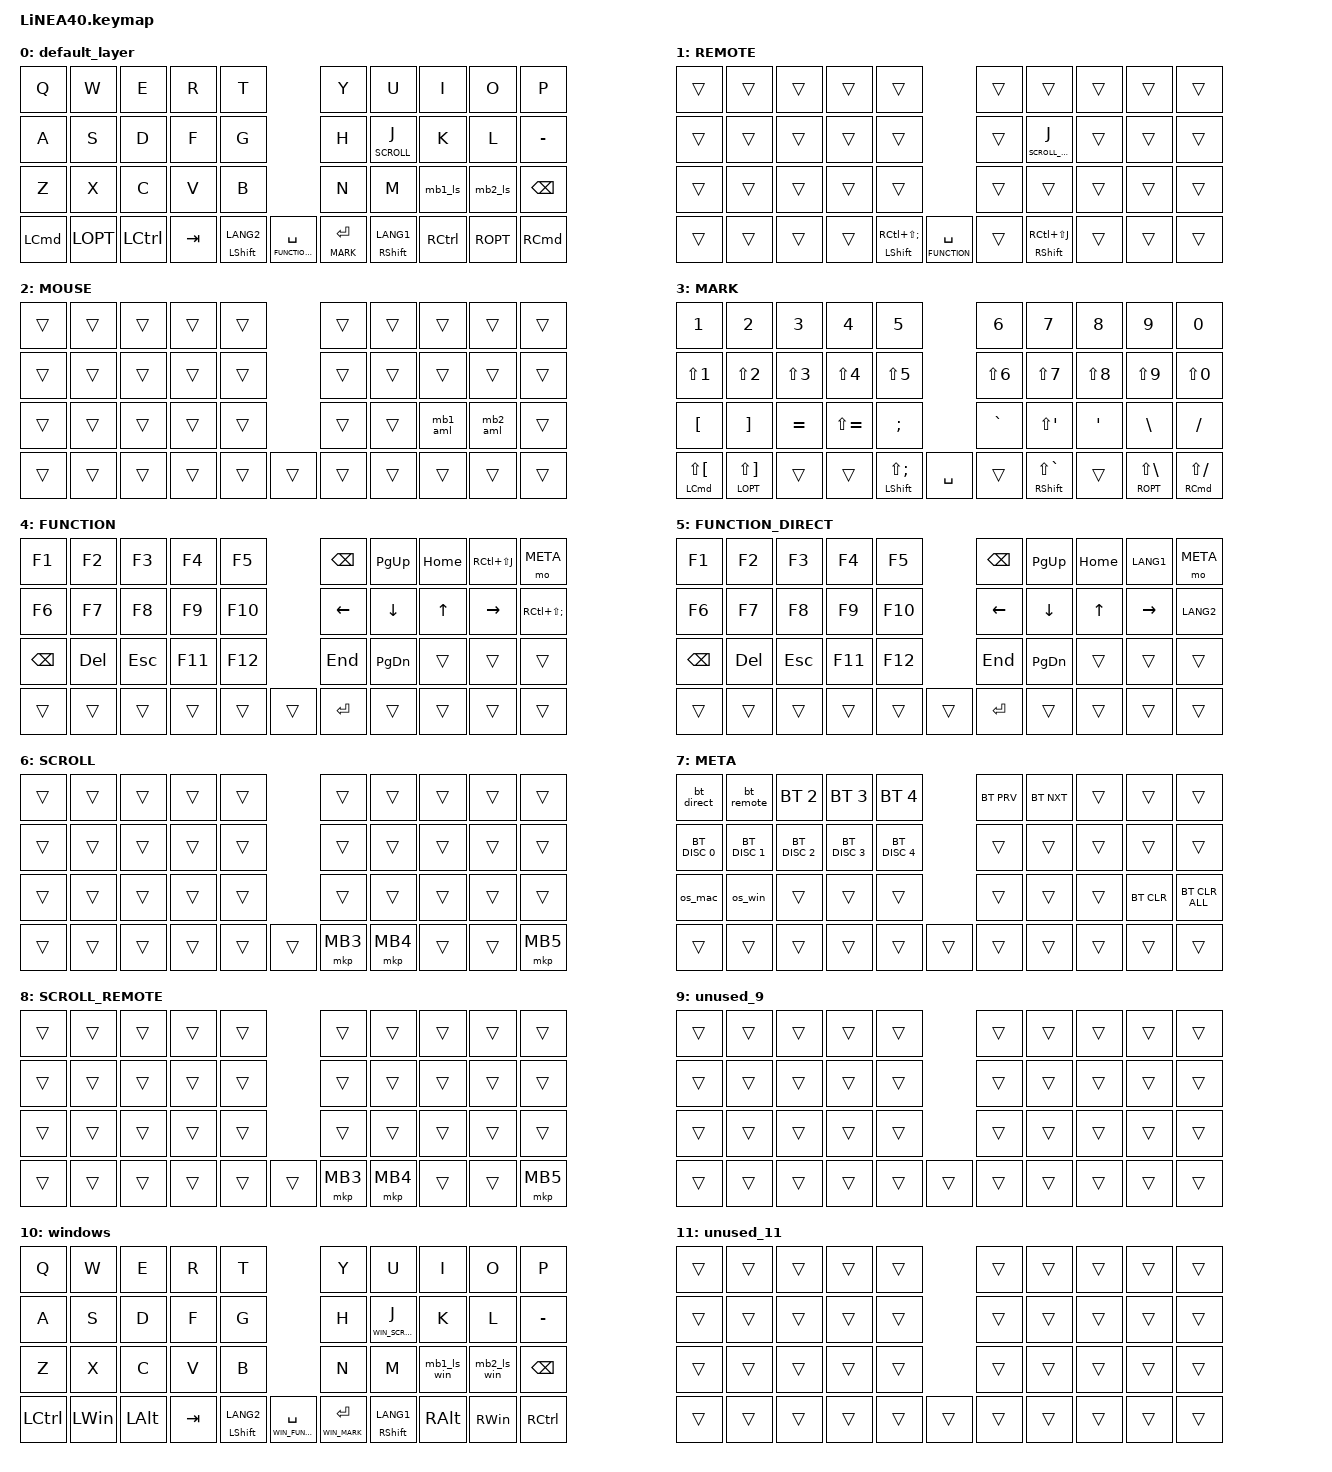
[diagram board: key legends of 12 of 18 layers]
#define ZMK_POINTING_DEFAULT_SCRL_VAL 150

#include <dt-bindings/zmk/input_transform.h>
#include <input/processors.dtsi>
#include <zephyr/dt-bindings/input/input-event-codes.h>
#include <behaviors.dtsi>
#include <dt-bindings/zmk/bt.h>
#include <dt-bindings/zmk/keys.h>
#include <dt-bindings/zmk/modifiers.h>
#include <dt-bindings/zmk/pointing.h>

// 0–8 Mac。10–17 Windows（下一桁が Mac と同じ。REMOTE / Jump Desktop 相当は空けておく）
#define REMOTE 1
#define MOUSE 2
#define MARK 3
#define FUNCTION 4
#define FUNCTION_DIRECT 5
#define SCROLL 6
#define META 7
#define SCROLL_REMOTE 8
// 9 は番号合わせの空き
#define WINDOWS 10
// 11 は REMOTE 相当の空き（Jump Desktop は Windows に無い）
#define WIN_MOUSE 12
#define WIN_MARK 13
// 14 は FUNCTION 相当の空き（Jump Desktop 用 FUNCTION は Windows に無い）
#define WIN_FUNCTION_DIRECT 15
#define WIN_SCROLL 16
#define WIN_META 17
#define AK_LAYER_MARK F21
// 起動時は Mac（直接接続）。英数は LANG2、かなは LANG1。再起動でも Mac に戻る。
// META / WIN_META の X で WINDOWS を基本レイヤーにする。Cmd→Ctrl、Opt→Win、Ctrl→Alt。Z で Mac に戻す。
// REMOTE は Mac の Jump Desktop 専用。英数は右Ctrl+Shift+;、かなは右Ctrl+Shift+J。Windows では乗せない。
// ボールは常に MOUSE を足す。Windows 基本のときは conditional で WIN_MOUSE に載せ替える。
// 文章操作のあと、句読点のままにする時間（ms）
#define AK_PUNCT_IDLE_MS 4000

#define LOPT LALT
#define ROPT RALT

&mt { flavor = "hold-preferred"; };

&lt { flavor = "hold-preferred"; };

//mouse cursol

&mmv {
    delay-ms = <20>;
    trigger-period-ms = <5>;
    time-to-max-speed-ms = <100>;
    acceleration-exponent = <2>;
};

//mouse scroll

&msc {
    delay-ms = <3>;
    trigger-period-ms = <3>;
    time-to-max-speed-ms = <100>;
    acceleration-exponent = <0>;
};

/ {
    input_processors {
        zip_wheel_scaler: zip_wheel_scaler {
            compatible = "zmk,input-processor-scaler";
            #input-processor-cells = <2>;
            type = <INPUT_EV_REL>;
            codes = <INPUT_REL_WHEEL>;
            track-remainders;
        };

        // ボール操作で MOUSE を乗せ、クリック以外のキーで外す（句読点クールタイムを打ち切る）
        zip_ak_mouse: zip_ak_mouse {
            compatible = "zmk,input-processor-temp-layer";
            #input-processor-cells = <2>;
            excluded-positions = <27 28>;
        };
    };
};

&msc_input_listener {
    speed_up {
        layers = <FUNCTION FUNCTION_DIRECT WIN_FUNCTION_DIRECT>;
        input-processors = <&zip_wheel_scaler 3 1>; //スクロールを3倍速にする
    };
};

&trackball_listener {
    input-processors = <&zip_ak_mouse MOUSE 1500>;

    scroller {
        layers = <SCROLL WIN_SCROLL>;
        input-processors =
            <&zip_ak_mouse MOUSE 1500>,
            // スクロール用に感度を小さくする,,,,,,,,,,,,,,
            <&zip_xy_scaler 1 30>,
            // スクロール方向を逆転,,,,,,,,,,,,,,
            <&zip_xy_transform INPUT_TRANSFORM_Y_INVERT>,
            // マウス移動をスクロールに割り当て,,,,,,,,,,,,,,
            <&zip_xy_to_scroll_mapper>;
    };

    // プロファイル1のホイール。縦は直接接続と逆、速度は半分（1/60）
    remote_scroller {
        layers = <SCROLL_REMOTE>;
        input-processors =
            <&zip_ak_mouse MOUSE 1500>,
            <&zip_xy_scaler 1 60>,
            <&zip_xy_to_scroll_mapper>;
    };
};

/ {
    combos { compatible = "zmk,combos"; };

    macros {
        // レイヤーを押しながら未使用キーをタップし、句読点判定の直前キーにする
        mo_ak: mo_ak {
            compatible = "zmk,behavior-macro-one-param";
            #binding-cells = <1>;
            wait-ms = <0>;
            tap-ms = <5>;
            bindings
                = <&macro_param_1to1>
                , <&macro_press &mo MACRO_PLACEHOLDER>
                , <&macro_tap &kp AK_LAYER_MARK>
                , <&macro_pause_for_release>
                , <&macro_param_1to1>
                , <&macro_release &mo MACRO_PLACEHOLDER>
                ;
        };
        // プロファイル0（直接接続）。キーを離してから REMOTE 層を外し、基本レイヤーに戻す
        bt_direct: bt_direct {
            compatible = "zmk,behavior-macro";
            #binding-cells = <0>;
            wait-ms = <0>;
            tap-ms = <0>;
            bindings
                = <&macro_tap &bt BT_SEL 0>
                , <&macro_pause_for_release>
                , <&macro_tap &to 0>
                ;
        };
        // プロファイル1（リモート接続）。キーを離してから REMOTE 層を足す
        bt_remote: bt_remote {
            compatible = "zmk,behavior-macro";
            #binding-cells = <0>;
            wait-ms = <0>;
            tap-ms = <0>;
            bindings
                = <&macro_tap &bt BT_SEL 1>
                , <&macro_pause_for_release>
                , <&macro_tap &to 0>
                , <&macro_tap &tog REMOTE>
                ;
        };
        // Windows 基本レイヤーのままプロファイル0へ。&to 0 だと Windows が外れる
        bt_direct_win: bt_direct_win {
            compatible = "zmk,behavior-macro";
            #binding-cells = <0>;
            wait-ms = <0>;
            tap-ms = <0>;
            bindings
                = <&macro_tap &bt BT_SEL 0>
                , <&macro_pause_for_release>
                , <&macro_tap &to WINDOWS>
                ;
        };
        // Windows 基本レイヤーのままプロファイル1へ。REMOTE は Mac の Jump Desktop 用なので乗せない
        bt_remote_win: bt_remote_win {
            compatible = "zmk,behavior-macro";
            #binding-cells = <0>;
            wait-ms = <0>;
            tap-ms = <0>;
            bindings
                = <&macro_tap &bt BT_SEL 1>
                , <&macro_pause_for_release>
                , <&macro_tap &to WINDOWS>
                ;
        };
        // META の Z。離してから Mac の基本レイヤーだけにする（REMOTE も外れる）
        os_mac: os_mac {
            compatible = "zmk,behavior-macro";
            #binding-cells = <0>;
            wait-ms = <0>;
            tap-ms = <0>;
            bindings
                = <&macro_pause_for_release>
                , <&macro_tap &to 0>
                ;
        };
        // META の X。離してから WINDOWS を基本レイヤーにする（REMOTE も外れる）
        os_win: os_win {
            compatible = "zmk,behavior-macro";
            #binding-cells = <0>;
            wait-ms = <0>;
            tap-ms = <0>;
            bindings
                = <&macro_pause_for_release>
                , <&macro_tap &to WINDOWS>
                ;
        };
    };

    behaviors {
        re_kp: sensor_rotate_kp {
            compatible = "zmk,behavior-sensor-rotate-var";
            #sensor-binding-cells = <2>;
            bindings = <&kp>, <&kp>;
        };

        mouse_scrl: mouse_wheel_scrl {
            compatible = "zmk,behavior-sensor-rotate-var";
            #sensor-binding-cells = <2>;
            bindings = <&msc>, <&msc>;

            tap-ms = <20>;
        };

        re_kp_delay: re_kp_delay {
            compatible = "zmk,behavior-sensor-rotate-var";
            label = "RE_KP_DELAY";
            #sensor-binding-cells = <2>;
            bindings = <&kp>, <&kp>;

            tap-ms = <50>;
        };

        // J: tap は文字、hold は SCROLL。次が文字・-・BS・,・. なら tap（連続入力）
        // hold 対象は親指だけ。句読点位置を入れると j, のロールがクリックになる
        // 押下直後から SCROLL を載せる。タップなら層を外してから文字を出す
        lsc: l_scroll {
            compatible = "zmk,behavior-hold-tap";
            #binding-cells = <2>;
            flavor = "hold-preferred";
            tapping-term-ms = <200>;
            require-prior-idle-ms = <125>;
            quick-tap-ms = <175>;
            hold-while-undecided;
            bindings = <&mo>, <&kp>;
            hold-trigger-key-positions = <30 31 32 33 34 35 36 37 38 39 40>;
        };

        // { } は連続入力が多いため、ほぼ同時押しでも修飾ではなくお互いのタップにする。
        // ZMKでは「このキーは連続入力」は直接指定できないので、
        // hold-trigger-key-positions は修飾にする相手キーなので、{ }（位置 30 31。Mac は左Cmd/左Opt、Windows は左Ctrl/左Win）を外して書く。
        mt_brace: mt_brace {
            compatible = "zmk,behavior-hold-tap";
            #binding-cells = <2>;
            flavor = "hold-preferred";
            tapping-term-ms = <200>;
            bindings = <&kp>, <&kp>;
            hold-trigger-key-positions = <
                0 1 2 3 4 5 6 7 8 9
                10 11 12 13 14 15 16 17 18 19
                20 21 22 23 24 25 26 27 28 29
                32 33 34 35 36 37 38 39 40
            >;
        };

        // tap は通常キー、hold は MARK/FUNCTION ＋句読点用マーカ
        ak_lt: adaptive_layer_tap {
            compatible = "zmk,behavior-hold-tap";
            #binding-cells = <2>;
            flavor = "hold-preferred";
            tapping-term-ms = <200>;
            bindings = <&mo_ak>, <&kp>;
        };

        // 直前が文字・文章操作（IME/移動/MARK・FUNCTION 入場）なら句読点、それ以外はマウスボタン
        ak_mb1: adaptive_mb1 {
            compatible = "zmk,behavior-adaptive-key";
            #binding-cells = <0>;
            bindings = <&mkp MB1>;
            dead-keys = <AK_LAYER_MARK>;

            after_alpha {
                trigger-keys = <A B C D E F G H I J K L M N O P Q R S T U V W X Y Z>;
                max-prior-idle-ms = <AK_PUNCT_IDLE_MS>;
                strict-modifiers;
                bindings = <&kp COMMA>;
            };
            after_ls {
                trigger-keys = <LS(A) LS(B) LS(C) LS(D) LS(E) LS(F) LS(G) LS(H) LS(I) LS(J) LS(K) LS(L) LS(M) LS(N) LS(O) LS(P) LS(Q) LS(R) LS(S) LS(T) LS(U) LS(V) LS(W) LS(X) LS(Y) LS(Z)>;
                max-prior-idle-ms = <AK_PUNCT_IDLE_MS>;
                strict-modifiers;
                bindings = <&kp COMMA>;
            };
            after_rs {
                trigger-keys = <RS(A) RS(B) RS(C) RS(D) RS(E) RS(F) RS(G) RS(H) RS(I) RS(J) RS(K) RS(L) RS(M) RS(N) RS(O) RS(P) RS(Q) RS(R) RS(S) RS(T) RS(U) RS(V) RS(W) RS(X) RS(Y) RS(Z)>;
                max-prior-idle-ms = <AK_PUNCT_IDLE_MS>;
                strict-modifiers;
                bindings = <&kp COMMA>;
            };
            after_edit {
                trigger-keys = <LC(C) LC(V) LC(X) RC(C) RC(V) RC(X) LG(C) LG(V) LG(X) RG(C) RG(V) RG(X)>;
                max-prior-idle-ms = <AK_PUNCT_IDLE_MS>;
                strict-modifiers;
                bindings = <&kp COMMA>;
            };
            after_other {
                trigger-keys = <N0 N1 N2 N3 N4 N5 N6 N7 N8 N9 SPACE RET BSPC MINUS COMMA DOT FSLH SEMI RC(LS(SEMI)) RC(LS(J)) LANG1 LANG2 LEFT RIGHT UP DOWN PG_UP PG_DN HOME END AK_LAYER_MARK>;
                max-prior-idle-ms = <AK_PUNCT_IDLE_MS>;
                bindings = <&kp COMMA>;
            };
        };

        ak_mb2: adaptive_mb2 {
            compatible = "zmk,behavior-adaptive-key";
            #binding-cells = <0>;
            bindings = <&mkp MB2>;
            dead-keys = <AK_LAYER_MARK>;

            after_alpha {
                trigger-keys = <A B C D E F G H I J K L M N O P Q R S T U V W X Y Z>;
                max-prior-idle-ms = <AK_PUNCT_IDLE_MS>;
                strict-modifiers;
                bindings = <&kp DOT>;
            };
            after_ls {
                trigger-keys = <LS(A) LS(B) LS(C) LS(D) LS(E) LS(F) LS(G) LS(H) LS(I) LS(J) LS(K) LS(L) LS(M) LS(N) LS(O) LS(P) LS(Q) LS(R) LS(S) LS(T) LS(U) LS(V) LS(W) LS(X) LS(Y) LS(Z)>;
                max-prior-idle-ms = <AK_PUNCT_IDLE_MS>;
                strict-modifiers;
                bindings = <&kp DOT>;
            };
            after_rs {
                trigger-keys = <RS(A) RS(B) RS(C) RS(D) RS(E) RS(F) RS(G) RS(H) RS(I) RS(J) RS(K) RS(L) RS(M) RS(N) RS(O) RS(P) RS(Q) RS(R) RS(S) RS(T) RS(U) RS(V) RS(W) RS(X) RS(Y) RS(Z)>;
                max-prior-idle-ms = <AK_PUNCT_IDLE_MS>;
                strict-modifiers;
                bindings = <&kp DOT>;
            };
            after_edit {
                trigger-keys = <LC(C) LC(V) LC(X) RC(C) RC(V) RC(X) LG(C) LG(V) LG(X) RG(C) RG(V) RG(X)>;
                max-prior-idle-ms = <AK_PUNCT_IDLE_MS>;
                strict-modifiers;
                bindings = <&kp DOT>;
            };
            after_other {
                trigger-keys = <N0 N1 N2 N3 N4 N5 N6 N7 N8 N9 SPACE RET BSPC MINUS COMMA DOT FSLH SEMI RC(LS(SEMI)) RC(LS(J)) LANG1 LANG2 LEFT RIGHT UP DOWN PG_UP PG_DN HOME END AK_LAYER_MARK>;
                max-prior-idle-ms = <AK_PUNCT_IDLE_MS>;
                bindings = <&kp DOT>;
            };
        };

        // 左Shiftはクリック（ドラッグ）。右Shiftは < >、右Cmdは , .
        mb1_rs: mb1_rs {
            compatible = "zmk,behavior-mod-morph";
            #binding-cells = <0>;
            bindings = <&ak_mb1>, <&kp COMMA>;
            mods = <(MOD_RSFT|MOD_RGUI)>;
            keep-mods = <(MOD_RSFT|MOD_RGUI)>;
        };
        mb1_ls: mb1_ls {
            compatible = "zmk,behavior-mod-morph";
            #binding-cells = <0>;
            bindings = <&mb1_rs>, <&mkp MB1>;
            mods = <(MOD_LSFT)>;
            keep-mods = <(MOD_LSFT)>;
        };
        mb2_rs: mb2_rs {
            compatible = "zmk,behavior-mod-morph";
            #binding-cells = <0>;
            bindings = <&ak_mb2>, <&kp DOT>;
            mods = <(MOD_RSFT|MOD_RGUI)>;
            keep-mods = <(MOD_RSFT|MOD_RGUI)>;
        };
        mb2_ls: mb2_ls {
            compatible = "zmk,behavior-mod-morph";
            #binding-cells = <0>;
            bindings = <&mb2_rs>, <&mkp MB2>;
            mods = <(MOD_LSFT)>;
            keep-mods = <(MOD_LSFT)>;
        };
        // AML 中は句読点判定を使わず、右Shiftは < >、右Cmdは , . にする
        mb1_aml: mb1_aml {
            compatible = "zmk,behavior-mod-morph";
            #binding-cells = <0>;
            bindings = <&mkp MB1>, <&kp COMMA>;
            mods = <(MOD_RSFT|MOD_RGUI)>;
            keep-mods = <(MOD_RSFT|MOD_RGUI)>;
        };
        mb2_aml: mb2_aml {
            compatible = "zmk,behavior-mod-morph";
            #binding-cells = <0>;
            bindings = <&mkp MB2>, <&kp DOT>;
            mods = <(MOD_RSFT|MOD_RGUI)>;
            keep-mods = <(MOD_RSFT|MOD_RGUI)>;
        };
        // Windows 写し。右Cmdの位置が右Ctrlになるので MOD_RCTL で見る
        mb1_rs_win: mb1_rs_win {
            compatible = "zmk,behavior-mod-morph";
            #binding-cells = <0>;
            bindings = <&ak_mb1>, <&kp COMMA>;
            mods = <(MOD_RSFT|MOD_RCTL)>;
            keep-mods = <(MOD_RSFT|MOD_RCTL)>;
        };
        mb1_ls_win: mb1_ls_win {
            compatible = "zmk,behavior-mod-morph";
            #binding-cells = <0>;
            bindings = <&mb1_rs_win>, <&mkp MB1>;
            mods = <(MOD_LSFT)>;
            keep-mods = <(MOD_LSFT)>;
        };
        mb2_rs_win: mb2_rs_win {
            compatible = "zmk,behavior-mod-morph";
            #binding-cells = <0>;
            bindings = <&ak_mb2>, <&kp DOT>;
            mods = <(MOD_RSFT|MOD_RCTL)>;
            keep-mods = <(MOD_RSFT|MOD_RCTL)>;
        };
        mb2_ls_win: mb2_ls_win {
            compatible = "zmk,behavior-mod-morph";
            #binding-cells = <0>;
            bindings = <&mb2_rs_win>, <&mkp MB2>;
            mods = <(MOD_LSFT)>;
            keep-mods = <(MOD_LSFT)>;
        };
        mb1_aml_win: mb1_aml_win {
            compatible = "zmk,behavior-mod-morph";
            #binding-cells = <0>;
            bindings = <&mkp MB1>, <&kp COMMA>;
            mods = <(MOD_RSFT|MOD_RCTL)>;
            keep-mods = <(MOD_RSFT|MOD_RCTL)>;
        };
        mb2_aml_win: mb2_aml_win {
            compatible = "zmk,behavior-mod-morph";
            #binding-cells = <0>;
            bindings = <&mkp MB2>, <&kp DOT>;
            mods = <(MOD_RSFT|MOD_RCTL)>;
            keep-mods = <(MOD_RSFT|MOD_RCTL)>;
        };
    };

    // ボールは常に MOUSE を足す。Windows 基本のときだけ WIN_MOUSE に載せ替える。
    // それ以外の Windows 層は基本レイヤー側の hold から直接入る（Mac 層と混ぜない）。
    conditional_layers {
        compatible = "zmk,conditional-layers";

        win_mouse_if {
            if-layers = <WINDOWS MOUSE>;
            then-layer = <WIN_MOUSE>;
        };
    };

    keymap {
        compatible = "zmk,keymap";

        // 0  Mac 基本。起動時ここ。

        default_layer {
            bindings = <
&kp Q     &kp W     &kp E      &kp R    &kp T                                          &kp Y  &kp U     &kp I      &kp O     &kp P
&kp A     &kp S     &kp D      &kp F    &kp G                                          &kp H  &lsc SCROLL J  &kp K      &kp L     &kp MINUS
&kp Z     &kp X     &kp C      &kp V    &kp B                                          &kp N  &kp M     &mb1_ls    &mb2_ls   &kp BSPC
&kp LCMD  &kp LOPT  &kp LCTRL  &kp TAB  &mt LSHFT LANG2  &ak_lt FUNCTION_DIRECT SPACE  &ak_lt MARK RET  &mt RSHFT LANG1  &kp RCTRL  &kp ROPT  &kp RCMD
            >;

            sensor-bindings = <&mouse_scrl SCRL_DOWN SCRL_UP>;
        };

        // 1  Mac の Jump Desktop。プロファイル1で足す。英数/かなと、そのときの FUNCTION だけ差し替える

        REMOTE {
            bindings = <
&trans  &trans  &trans  &trans  &trans                                          &trans  &trans  &trans  &trans  &trans
&trans  &trans  &trans  &trans  &trans                                          &trans  &lsc SCROLL_REMOTE J  &trans  &trans  &trans
&trans  &trans  &trans  &trans  &trans                                          &trans  &trans  &trans  &trans  &trans
&trans  &trans  &trans  &trans  &mt LSHFT RC(LS(SEMI))  &ak_lt FUNCTION SPACE  &trans  &mt RSHFT RC(LS(J))  &trans  &trans  &trans
            >;
        };

        // 2  Mac。ボール操作中

        MOUSE {
            bindings = <
&trans  &trans  &trans  &trans  &trans                  &trans  &trans  &trans    &trans    &trans
&trans  &trans  &trans  &trans  &trans                  &trans  &trans  &trans    &trans    &trans
&trans  &trans  &trans  &trans  &trans                  &trans  &trans  &mb1_aml  &mb2_aml  &trans
&trans  &trans  &trans  &trans  &trans  &trans  &trans  &trans          &trans    &trans    &trans
            >;
        };

        // 3  Mac 記号

        MARK {
            bindings = <
&kp N1                   &kp N2                   &kp N3      &kp N4         &kp N5                                 &kp N6               &kp N7       &kp N8      &kp N9             &kp N0
&kp LS(N1)               &kp LS(N2)               &kp LS(N3)  &kp LS(N4)     &kp LS(N5)                             &kp LS(N6)           &kp LS(N7)   &kp LS(N8)  &kp LS(N9)         &kp LS(N0)
&kp LBKT                 &kp RBKT                 &kp EQUAL   &kp LS(EQUAL)  &kp SEMI                               &kp GRAVE            &kp LS(SQT)  &kp SQT     &kp BSLH           &kp FSLH
&mt_brace LCMD LS(LBKT)  &mt_brace LOPT LS(RBKT)  &trans      &trans         &mt LSHFT LS(SEMI)  &kp SPACE  &trans  &mt RSHFT LS(GRAVE)               &trans      &mt ROPT LS(BSLH)  &mt RCMD LS(FSLH)
            >;

            sensor-bindings = <&re_kp C_VOL_DN C_VOL_UP>;
        };

        // 4  Mac Jump Desktop の FUNCTION

        FUNCTION {
            bindings = <
&kp F1    &kp F2   &kp F3   &kp F4   &kp F5                    &kp BSPC  &kp PG_UP  &kp HOME  &kp RC(LS(J))  &mo META
&kp F6    &kp F7   &kp F8   &kp F9   &kp F10                   &kp LEFT  &kp DOWN   &kp UP    &kp RIGHT  &kp RC(LS(SEMI))
&kp BSPC  &kp DEL  &kp ESC  &kp F11  &kp F12                   &kp END   &kp PG_DN  &trans    &trans    &trans
&trans    &trans   &trans   &trans   &trans   &trans  &kp RET  &trans               &trans    &trans     &trans
            >;

            sensor-bindings = <&mouse_scrl SCRL_DOWN SCRL_UP>;
        };

        // 5  Mac 直接接続の FUNCTION。英数は LANG2、かなは LANG1

        FUNCTION_DIRECT {
            bindings = <
&kp F1    &kp F2   &kp F3   &kp F4   &kp F5                    &kp BSPC  &kp PG_UP  &kp HOME  &kp LANG1  &mo META
&kp F6    &kp F7   &kp F8   &kp F9   &kp F10                   &kp LEFT  &kp DOWN   &kp UP    &kp RIGHT  &kp LANG2
&kp BSPC  &kp DEL  &kp ESC  &kp F11  &kp F12                   &kp END   &kp PG_DN  &trans    &trans    &trans
&trans    &trans   &trans   &trans   &trans   &trans  &kp RET  &trans               &trans    &trans     &trans
            >;

            sensor-bindings = <&mouse_scrl SCRL_DOWN SCRL_UP>;
        };

        // 6  Mac ホイール

        SCROLL {
            bindings = <
&trans  &trans  &trans  &trans  &trans                    &trans  &trans  &trans  &trans  &trans
&trans  &trans  &trans  &trans  &trans                    &trans  &trans  &trans  &trans  &trans
&trans  &trans  &trans  &trans  &trans                    &trans  &trans  &trans  &trans  &trans
&trans  &trans  &trans  &trans  &trans  &trans  &mkp MB3  &mkp MB4        &trans  &trans  &mkp MB5
            >;
        };

        // 7  Mac Bluetooth。FUNCTION の P をホールドして入る。Z が Mac、X が Windows

        META {
            bindings = <
&bt_direct       &bt_remote   &bt BT_SEL 2   &bt BT_SEL 3   &bt BT_SEL 4                    &bt BT_PRV  &bt BT_NXT  &trans  &trans  &trans
&bt BT_DISC 0  &bt BT_DISC 1  &bt BT_DISC 2  &bt BT_DISC 3  &bt BT_DISC 4                   &trans      &trans      &trans  &trans  &trans
&os_mac        &os_win        &trans         &trans         &trans                          &trans      &trans      &trans  &bt BT_CLR  &bt BT_CLR_ALL
&trans         &trans         &trans         &trans         &trans        &trans  &trans    &trans                  &trans  &trans  &trans
            >;
        };

        // 8  Mac Jump Desktop のホイール。向きは直接接続と逆、速度は半分（1/60）

        SCROLL_REMOTE {
            bindings = <
&trans  &trans  &trans  &trans  &trans                    &trans  &trans  &trans  &trans  &trans
&trans  &trans  &trans  &trans  &trans                    &trans  &trans  &trans  &trans  &trans
&trans  &trans  &trans  &trans  &trans                    &trans  &trans  &trans  &trans  &trans
&trans  &trans  &trans  &trans  &trans  &trans  &mkp MB3  &mkp MB4        &trans  &trans  &mkp MB5
            >;
        };

        // 9  Windows を 10 から始めるための空き。入らない

        unused_9 {
            bindings = <
&trans  &trans  &trans  &trans  &trans                  &trans  &trans  &trans  &trans  &trans
&trans  &trans  &trans  &trans  &trans                  &trans  &trans  &trans  &trans  &trans
&trans  &trans  &trans  &trans  &trans                  &trans  &trans  &trans  &trans  &trans
&trans  &trans  &trans  &trans  &trans  &trans  &trans  &trans          &trans  &trans  &trans
            >;
        };

        // 10  Windows 基本（= Mac 0）。hold 先も Windows 側だけを指す

        windows {
            bindings = <
&kp Q     &kp W     &kp E      &kp R    &kp T                                                  &kp Y  &kp U     &kp I      &kp O     &kp P
&kp A     &kp S     &kp D      &kp F    &kp G                                                  &kp H  &lsc WIN_SCROLL J  &kp K      &kp L     &kp MINUS
&kp Z     &kp X     &kp C      &kp V    &kp B                                                  &kp N  &kp M     &mb1_ls_win  &mb2_ls_win  &kp BSPC
&kp LCTRL &kp LWIN  &kp LALT   &kp TAB  &mt LSHFT LANG2  &ak_lt WIN_FUNCTION_DIRECT SPACE  &ak_lt WIN_MARK RET  &mt RSHFT LANG1  &kp RALT  &kp RWIN  &kp RCTRL
            >;

            sensor-bindings = <&mouse_scrl SCRL_DOWN SCRL_UP>;
        };

        // 11  REMOTE（1）相当の空き。Jump Desktop は Windows に無い

        unused_11 {
            bindings = <
&trans  &trans  &trans  &trans  &trans                  &trans  &trans  &trans  &trans  &trans
&trans  &trans  &trans  &trans  &trans                  &trans  &trans  &trans  &trans  &trans
&trans  &trans  &trans  &trans  &trans                  &trans  &trans  &trans  &trans  &trans
&trans  &trans  &trans  &trans  &trans  &trans  &trans  &trans          &trans  &trans  &trans
            >;
        };

        // 12  Windows ボール（= Mac MOUSE 2）。WINDOWS+MOUSE のとき conditional で乗る

        win_mouse {
            bindings = <
&trans  &trans  &trans  &trans  &trans                  &trans  &trans  &trans         &trans         &trans
&trans  &trans  &trans  &trans  &trans                  &trans  &trans  &trans         &trans         &trans
&trans  &trans  &trans  &trans  &trans                  &trans  &trans  &mb1_aml_win   &mb2_aml_win   &trans
&trans  &trans  &trans  &trans  &trans  &trans  &trans  &trans             &trans         &trans         &trans
            >;
        };

        // 13  Windows 記号（= Mac MARK 3）

        win_mark {
            bindings = <
&kp N1                    &kp N2                    &kp N3      &kp N4         &kp N5                                 &kp N6               &kp N7       &kp N8      &kp N9              &kp N0
&kp LS(N1)                &kp LS(N2)                &kp LS(N3)  &kp LS(N4)     &kp LS(N5)                             &kp LS(N6)           &kp LS(N7)   &kp LS(N8)  &kp LS(N9)          &kp LS(N0)
&kp LBKT                  &kp RBKT                  &kp EQUAL   &kp LS(EQUAL)  &kp SEMI                               &kp GRAVE            &kp LS(SQT)  &kp SQT     &kp BSLH            &kp FSLH
&mt_brace LCTRL LS(LBKT)  &mt_brace LWIN LS(RBKT)   &trans      &trans         &mt LSHFT LS(SEMI)  &kp SPACE  &trans  &mt RSHFT LS(GRAVE)               &trans      &mt RWIN LS(BSLH)   &mt RCTRL LS(FSLH)
            >;

            sensor-bindings = <&re_kp C_VOL_DN C_VOL_UP>;
        };

        // 14  FUNCTION（4）相当の空き。Jump Desktop 用 FUNCTION は Windows に無い

        unused_14 {
            bindings = <
&trans  &trans  &trans  &trans  &trans                  &trans  &trans  &trans  &trans  &trans
&trans  &trans  &trans  &trans  &trans                  &trans  &trans  &trans  &trans  &trans
&trans  &trans  &trans  &trans  &trans                  &trans  &trans  &trans  &trans  &trans
&trans  &trans  &trans  &trans  &trans  &trans  &trans  &trans          &trans  &trans  &trans
            >;
        };

        // 15  Windows FUNCTION（= Mac FUNCTION_DIRECT 5）。META だけ WIN_META

        win_function_direct {
            bindings = <
&kp F1    &kp F2   &kp F3   &kp F4   &kp F5                    &kp BSPC  &kp PG_UP  &kp HOME  &kp LANG1  &mo WIN_META
&kp F6    &kp F7   &kp F8   &kp F9   &kp F10                   &kp LEFT  &kp DOWN   &kp UP    &kp RIGHT  &kp LANG2
&kp BSPC  &kp DEL  &kp ESC  &kp F11  &kp F12                   &kp END   &kp PG_DN  &trans    &trans    &trans
&trans    &trans   &trans   &trans   &trans   &trans  &kp RET  &trans               &trans    &trans     &trans
            >;

            sensor-bindings = <&mouse_scrl SCRL_DOWN SCRL_UP>;
        };

        // 16  Windows ホイール（= Mac SCROLL 6）

        win_scroll {
            bindings = <
&trans  &trans  &trans  &trans  &trans                    &trans  &trans  &trans  &trans  &trans
&trans  &trans  &trans  &trans  &trans                    &trans  &trans  &trans  &trans  &trans
&trans  &trans  &trans  &trans  &trans                    &trans  &trans  &trans  &trans  &trans
&trans  &trans  &trans  &trans  &trans  &trans  &mkp MB3  &mkp MB4        &trans  &trans  &mkp MB5
            >;
        };

        // 17  Windows Bluetooth（= Mac META 7）。プロファイル 0/1 でも Windows のまま。REMOTE は乗せない

        win_meta {
            bindings = <
&bt_direct_win  &bt_remote_win  &bt BT_SEL 2   &bt BT_SEL 3   &bt BT_SEL 4                    &bt BT_PRV  &bt BT_NXT  &trans  &trans  &trans
&bt BT_DISC 0   &bt BT_DISC 1   &bt BT_DISC 2  &bt BT_DISC 3  &bt BT_DISC 4                   &trans      &trans      &trans  &trans  &trans
&os_mac         &os_win         &trans         &trans         &trans                          &trans      &trans      &trans  &bt BT_CLR  &bt BT_CLR_ALL
&trans          &trans          &trans         &trans         &trans        &trans  &trans    &trans                  &trans  &trans  &trans
            >;
        };
    };
};
